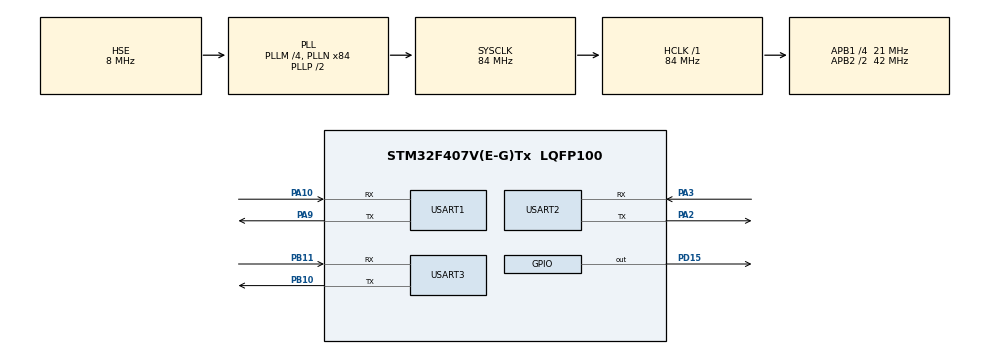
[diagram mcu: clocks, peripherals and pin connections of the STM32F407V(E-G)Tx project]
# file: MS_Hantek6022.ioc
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Mcu.Family=STM32F4
Mcu.Name=STM32F407V(E-G)Tx
Mcu.Package=LQFP100
NVIC.PriorityGroup=NVIC_PRIORITYGROUP_0
NVIC.TIM2_IRQn=true\:0\:0\:false\:false\:true\:true\:true\:true
NVIC.USART1_IRQn=true\:0\:0\:false\:false\:true\:true\:true\:true
NVIC.USART2_IRQn=true\:0\:0\:false\:false\:true\:true\:true\:true
NVIC.USART3_IRQn=true\:0\:0\:false\:false\:true\:true\:true\:true
PA10.Mode=Asynchronous
PA10.Signal=USART1_RX
PA2.Mode=Asynchronous
PA2.Signal=USART2_TX
PA3.Mode=Asynchronous
PA3.Signal=USART2_RX
PA9.Mode=Asynchronous
PA9.Signal=USART1_TX
PB10.Mode=Asynchronous
PB10.Signal=USART3_TX
PB11.Mode=Asynchronous
PB11.Signal=USART3_RX
PD15.Signal=GPIO_Output
PH0-OSC_IN.Mode=HSE-External-Oscillator
PH0-OSC_IN.Signal=RCC_OSC_IN
PH1-OSC_OUT.Mode=HSE-External-Oscillator
PH1-OSC_OUT.Signal=RCC_OSC_OUT
ProjectManager.HeapSize=0x200
ProjectManager.StackSize=0x400
ProjectManager.TargetToolchain=STM32CubeIDE
RCC.48MHZClocksFreq_Value=24000000
RCC.AHBFreq_Value=84000000
RCC.APB1CLKDivider=RCC_HCLK_DIV4
RCC.APB1Freq_Value=21000000
RCC.APB1TimFreq_Value=42000000
RCC.APB2CLKDivider=RCC_HCLK_DIV2
RCC.APB2Freq_Value=42000000
RCC.APB2TimFreq_Value=84000000
RCC.CortexFreq_Value=84000000
RCC.HCLKFreq_Value=84000000
RCC.HSE_VALUE=8000000
RCC.HSI_VALUE=16000000
RCC.PLLM=4
RCC.PLLN=84
RCC.PLLQ=7
RCC.PLLSourceVirtual=RCC_PLLSOURCE_HSE
RCC.SYSCLKFreq_VALUE=84000000
RCC.SYSCLKSource=RCC_SYSCLKSOURCE_PLLCLK
RCC.VCOOutputFreq_Value=168000000
TIM2.Period=1000
TIM2.Prescaler=42000-1
USART1.VirtualMode=VM_ASYNC
USART2.VirtualMode=VM_ASYNC
USART3.VirtualMode=VM_ASYNC
VP_TIM2_VS_ClockSourceINT.Mode=Internal
board=STM32F407G-DISC1

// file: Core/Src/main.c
/* USER CODE BEGIN Header */
/**
  ******************************************************************************
  * @file           : main.c
  * @brief          : Main program body
  ******************************************************************************
  * @attention
  *
  * Copyright (c) 2023 STMicroelectronics.
  * All rights reserved.
  *
  * This software is licensed under terms that can be found in the LICENSE file
  * in the root directory of this software component.
  * If no LICENSE file comes with this software, it is provided AS-IS.
  *
  ******************************************************************************
  */
/* USER CODE END Header */
#include "main.h"

TIM_HandleTypeDef htim2;

UART_HandleTypeDef huart1;
UART_HandleTypeDef huart2;
UART_HandleTypeDef huart3;

void SystemClock_Config(void);
static void MX_GPIO_Init(void);
static void MX_TIM2_Init(void);
static void MX_USART1_UART_Init(void);
static void MX_USART2_UART_Init(void);
static void MX_USART3_UART_Init(void);

/* USER CODE BEGIN 0 */
uint8_t c = 0b10101011;
uint8_t c4[4] = {0x06, 0x05, 0x02, 0x01};
uint8_t input;
uint8_t i;
/* USER CODE END 0 */

int main(void)
{

  /* MCU Configuration--------------------------------------------------------*/

  /* Reset of all peripherals, Initializes the Flash interface and the Systick. */
  HAL_Init();

  /* Configure the system clock */
  SystemClock_Config();

  /* Initialize all configured peripherals */
  MX_GPIO_Init();
  MX_TIM2_Init();
  MX_USART1_UART_Init();
  MX_USART2_UART_Init();
  MX_USART3_UART_Init();
  /* USER CODE BEGIN 2 */
  HAL_TIM_Base_Start_IT(&htim2);
  HAL_UART_Receive_IT(&huart3, &input, 1);
  /* USER CODE END 2 */

  /* Infinite loop */
  while (1)
  {

  }
}

void SystemClock_Config(void)
{
  RCC_OscInitTypeDef RCC_OscInitStruct = {0};
  RCC_ClkInitTypeDef RCC_ClkInitStruct = {0};

  /** Configure the main internal regulator output voltage
  */
  __HAL_RCC_PWR_CLK_ENABLE();
  __HAL_PWR_VOLTAGESCALING_CONFIG(PWR_REGULATOR_VOLTAGE_SCALE1);

  /** Initializes the RCC Oscillators according to the specified parameters
  * in the RCC_OscInitTypeDef structure.
  */
  RCC_OscInitStruct.OscillatorType = RCC_OSCILLATORTYPE_HSE;
  RCC_OscInitStruct.HSEState = RCC_HSE_ON;
  RCC_OscInitStruct.PLL.PLLState = RCC_PLL_ON;
  RCC_OscInitStruct.PLL.PLLSource = RCC_PLLSOURCE_HSE;
  RCC_OscInitStruct.PLL.PLLM = 4;
  RCC_OscInitStruct.PLL.PLLN = 84;
  RCC_OscInitStruct.PLL.PLLP = RCC_PLLP_DIV2;
  RCC_OscInitStruct.PLL.PLLQ = 7;
  if (HAL_RCC_OscConfig(&RCC_OscInitStruct) != HAL_OK)
  {
    Error_Handler();
  }

  /** Initializes the CPU, AHB and APB buses clocks
  */
  RCC_ClkInitStruct.ClockType = RCC_CLOCKTYPE_HCLK|RCC_CLOCKTYPE_SYSCLK
                              |RCC_CLOCKTYPE_PCLK1|RCC_CLOCKTYPE_PCLK2;
  RCC_ClkInitStruct.SYSCLKSource = RCC_SYSCLKSOURCE_PLLCLK;
  RCC_ClkInitStruct.AHBCLKDivider = RCC_SYSCLK_DIV1;
  RCC_ClkInitStruct.APB1CLKDivider = RCC_HCLK_DIV4;
  RCC_ClkInitStruct.APB2CLKDivider = RCC_HCLK_DIV2;

  if (HAL_RCC_ClockConfig(&RCC_ClkInitStruct, FLASH_LATENCY_2) != HAL_OK)
  {
    Error_Handler();
  }
}

static void MX_TIM2_Init(void)
{

  TIM_ClockConfigTypeDef sClockSourceConfig = {0};
  TIM_MasterConfigTypeDef sMasterConfig = {0};

  htim2.Instance = TIM2;
  htim2.Init.Prescaler = 42000-1;
  htim2.Init.CounterMode = TIM_COUNTERMODE_UP;
  htim2.Init.Period = 1000;
  htim2.Init.ClockDivision = TIM_CLOCKDIVISION_DIV1;
  htim2.Init.AutoReloadPreload = TIM_AUTORELOAD_PRELOAD_DISABLE;
  if (HAL_TIM_Base_Init(&htim2) != HAL_OK)
  {
    Error_Handler();
  }
  sClockSourceConfig.ClockSource = TIM_CLOCKSOURCE_INTERNAL;
  if (HAL_TIM_ConfigClockSource(&htim2, &sClockSourceConfig) != HAL_OK)
  {
    Error_Handler();
  }
  sMasterConfig.MasterOutputTrigger = TIM_TRGO_RESET;
  sMasterConfig.MasterSlaveMode = TIM_MASTERSLAVEMODE_DISABLE;
  if (HAL_TIMEx_MasterConfigSynchronization(&htim2, &sMasterConfig) != HAL_OK)
  {
    Error_Handler();
  }

}

static void MX_USART1_UART_Init(void)
{

  huart1.Instance = USART1;
  huart1.Init.BaudRate = 115200;
  huart1.Init.WordLength = UART_WORDLENGTH_8B;
  huart1.Init.StopBits = UART_STOPBITS_1;
  huart1.Init.Parity = UART_PARITY_NONE;
  huart1.Init.Mode = UART_MODE_TX_RX;
  huart1.Init.HwFlowCtl = UART_HWCONTROL_NONE;
  huart1.Init.OverSampling = UART_OVERSAMPLING_16;
  if (HAL_UART_Init(&huart1) != HAL_OK)
  {
    Error_Handler();
  }

}

static void MX_USART2_UART_Init(void)
{

  huart2.Instance = USART2;
  huart2.Init.BaudRate = 115200;
  huart2.Init.WordLength = UART_WORDLENGTH_8B;
  huart2.Init.StopBits = UART_STOPBITS_1;
  huart2.Init.Parity = UART_PARITY_NONE;
  huart2.Init.Mode = UART_MODE_TX_RX;
  huart2.Init.HwFlowCtl = UART_HWCONTROL_NONE;
  huart2.Init.OverSampling = UART_OVERSAMPLING_16;
  if (HAL_UART_Init(&huart2) != HAL_OK)
  {
    Error_Handler();
  }

}

static void MX_USART3_UART_Init(void)
{

  huart3.Instance = USART3;
  huart3.Init.BaudRate = 115200;
  huart3.Init.WordLength = UART_WORDLENGTH_8B;
  huart3.Init.StopBits = UART_STOPBITS_1;
  huart3.Init.Parity = UART_PARITY_NONE;
  huart3.Init.Mode = UART_MODE_TX_RX;
  huart3.Init.HwFlowCtl = UART_HWCONTROL_NONE;
  huart3.Init.OverSampling = UART_OVERSAMPLING_16;
  if (HAL_UART_Init(&huart3) != HAL_OK)
  {
    Error_Handler();
  }

}

static void MX_GPIO_Init(void)
{
  GPIO_InitTypeDef GPIO_InitStruct = {0};

  /* GPIO Ports Clock Enable */
  __HAL_RCC_GPIOH_CLK_ENABLE();
  __HAL_RCC_GPIOA_CLK_ENABLE();
  __HAL_RCC_GPIOB_CLK_ENABLE();
  __HAL_RCC_GPIOD_CLK_ENABLE();

  /*Configure GPIO pin Output Level */
  HAL_GPIO_WritePin(GPIOD, GPIO_PIN_15, GPIO_PIN_RESET);

  /*Configure GPIO pin : PD15 */
  GPIO_InitStruct.Pin = GPIO_PIN_15;
  GPIO_InitStruct.Mode = GPIO_MODE_OUTPUT_PP;
  GPIO_InitStruct.Pull = GPIO_NOPULL;
  GPIO_InitStruct.Speed = GPIO_SPEED_FREQ_LOW;
  HAL_GPIO_Init(GPIOD, &GPIO_InitStruct);

}

/* USER CODE BEGIN 4 */
void HAL_TIM_PeriodElapsedCallback(TIM_HandleTypeDef *htim)
{
 if(htim-> Instance == htim2.Instance){
	// HAL_UART_Transmit(&huart2, &c, 1, 100);
	 HAL_UART_Transmit(&huart2, &c4, 4, 100);
	 HAL_UART_Receive_IT(&huart3, &input, 1);
  HAL_GPIO_TogglePin(GPIOD, GPIO_PIN_15);
 }
}
/* USER CODE END 4 */

void Error_Handler(void)
{
  __disable_irq();
  while (1)
  {
  }
}
